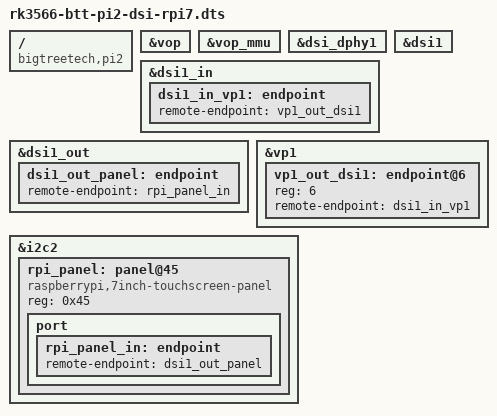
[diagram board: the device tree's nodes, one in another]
/dts-v1/;
/plugin/;

/*
 * BigTreeTech Pi2 / CB2 (RK3566) — enable the MIPI-DSI pipeline for an
 * RPi-7"-touchscreen-style panel (TC358762 DSI->DPI bridge + 0x45 panel MCU).
 *
 * Display is driven entirely by the in-tree all-in-one driver
 * `raspberrypi,7inch-touchscreen-panel` (CONFIG_DRM_PANEL_RASPBERRYPI_TOUCHSCREEN),
 * which programs the Toshiba bridge AND the 0x45 MCU itself over I2C2.
 * No tc358762 / attiny modules are required.
 *
 * Routing: VOP -> VP1 -> DSI1 -> panel.  (HDMI on this board uses VP0, so DSI uses VP1.)
 * Stock CB2 dtsi leaves &i2c2 disabled, so we enable it here too.
 *
 * TOUCH is handled in userspace (FT5406 @ i2c-2 0x38 has no host IRQ line on the
 * 15-pin DSI FFC, so it must be polled) — see ft5406_touch.c. We deliberately do
 * NOT add a 0x38 kernel node, leaving the address free for the userspace poller.
 */

/ {
	compatible = "bigtreetech,pi2", "rockchip,rk3566";
};

&vop      { status = "okay"; };
&vop_mmu  { status = "okay"; };
&dsi_dphy1 { status = "okay"; };
&dsi1     { status = "okay"; };

&dsi1_in {
	dsi1_in_vp1: endpoint {
		remote-endpoint = <&vp1_out_dsi1>;
	};
};

&dsi1_out {
	dsi1_out_panel: endpoint {
		remote-endpoint = <&rpi_panel_in>;
	};
};

&vp1 {
	/* reg 6 = ROCKCHIP_VOP2_EP_MIPI1 (dsi1) */
	vp1_out_dsi1: endpoint@6 {
		reg = <6>;
		remote-endpoint = <&dsi1_in_vp1>;
	};
};

&i2c2 {
	status = "okay";

	rpi_panel: panel@45 {
		compatible = "raspberrypi,7inch-touchscreen-panel";
		reg = <0x45>;

		port {
			rpi_panel_in: endpoint {
				remote-endpoint = <&dsi1_out_panel>;
			};
		};
	};
};
